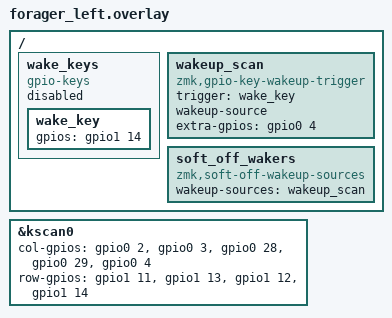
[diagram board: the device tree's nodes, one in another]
#include "forager.dtsi"

&kscan0 {
   col-gpios
   = <&gpio0 2 GPIO_ACTIVE_HIGH>
   , <&gpio0 3 GPIO_ACTIVE_HIGH>
   , <&gpio0 28 GPIO_ACTIVE_HIGH>
   , <&gpio0 29 GPIO_ACTIVE_HIGH>
   , <&gpio0 4 GPIO_ACTIVE_HIGH>
   ;

   row-gpios
   = <&gpio1 11 (GPIO_ACTIVE_HIGH | GPIO_PULL_DOWN)>
   , <&gpio1 13 (GPIO_ACTIVE_HIGH | GPIO_PULL_DOWN)>
   , <&gpio1 12 (GPIO_ACTIVE_HIGH | GPIO_PULL_DOWN)>
   , <&gpio1 14 (GPIO_ACTIVE_HIGH | GPIO_PULL_DOWN)>
   ;
};
/*
 * Soft-off wake key: the inner thumb key (row 3 P1.14, column 4 P0.04).
 * The gpio-keys node only names the pin for the waker; it stays disabled so
 * the Zephyr gpio-keys driver does not fight the matrix scan for it.
 */
/ {
    wake_keys {
        compatible = "gpio-keys";
        status = "disabled";
        wake_key: wake_key {
            gpios = <&gpio1 14 (GPIO_ACTIVE_HIGH | GPIO_PULL_DOWN)>;
        };
    };

    wakeup_scan: wakeup_scan {
        compatible = "zmk,gpio-key-wakeup-trigger";
        trigger = <&wake_key>;
        wakeup-source;
        extra-gpios = <&gpio0 4 GPIO_ACTIVE_HIGH>;
    };

    soft_off_wakers {
        compatible = "zmk,soft-off-wakeup-sources";
        wakeup-sources = <&wakeup_scan>;
    };
};
